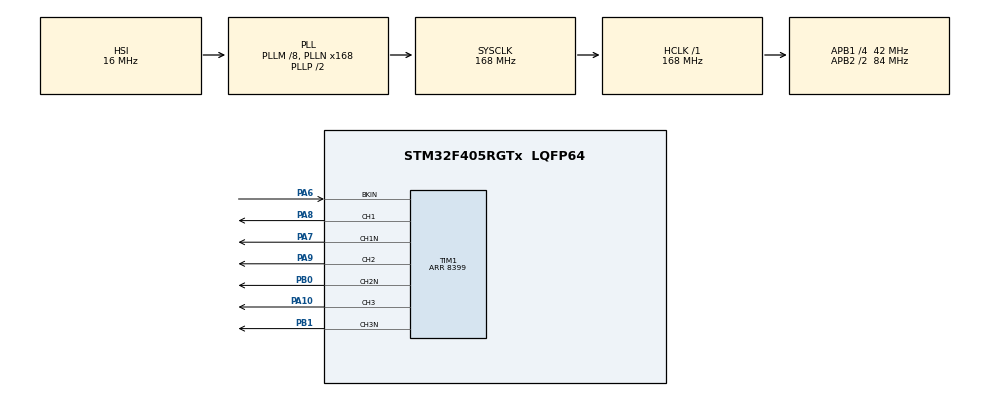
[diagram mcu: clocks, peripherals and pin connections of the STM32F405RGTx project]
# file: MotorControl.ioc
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Mcu.Family=STM32F4
Mcu.Name=STM32F405RGTx
Mcu.Package=LQFP64
NVIC.PriorityGroup=NVIC_PRIORITYGROUP_4
NVIC.TIM6_DAC_IRQn=true\:0\:0\:false\:false\:true\:true\:true\:true
PA10.Signal=S_TIM1_CH3
PA13.Mode=Serial_Wire
PA13.Signal=SYS_JTMS-SWDIO
PA14.Mode=Serial_Wire
PA14.Signal=SYS_JTCK-SWCLK
PA6.Mode=Activate-Break-Input
PA6.Signal=TIM1_BKIN
PA7.Mode=Output Compare1 CH1 CH1N
PA7.Signal=TIM1_CH1N
PA8.Signal=S_TIM1_CH1
PA9.Signal=S_TIM1_CH2
PB0.Mode=PWM Generation2 CH2 CH2N
PB0.Signal=TIM1_CH2N
PB1.Mode=Output Compare3 CH3 CH3N
PB1.Signal=TIM1_CH3N
PH0-OSC_IN.Mode=HSE-External-Oscillator
PH0-OSC_IN.Signal=RCC_OSC_IN
PH1-OSC_OUT.Mode=HSE-External-Oscillator
PH1-OSC_OUT.Signal=RCC_OSC_OUT
ProjectManager.HeapSize=0x200
ProjectManager.StackSize=0x400
ProjectManager.TargetToolchain=CMake
RCC.48MHZClocksFreq_Value=84000000
RCC.AHBFreq_Value=168000000
RCC.APB1CLKDivider=RCC_HCLK_DIV4
RCC.APB1Freq_Value=42000000
RCC.APB1TimFreq_Value=84000000
RCC.APB2CLKDivider=RCC_HCLK_DIV2
RCC.APB2Freq_Value=84000000
RCC.APB2TimFreq_Value=168000000
RCC.CortexFreq_Value=168000000
RCC.HCLKFreq_Value=168000000
RCC.HSE_VALUE=25000000
RCC.HSI_VALUE=16000000
RCC.LSE_VALUE=32768
RCC.PLLM=8
RCC.PLLN=168
RCC.SYSCLKFreq_VALUE=168000000
RCC.SYSCLKSource=RCC_SYSCLKSOURCE_PLLCLK
RCC.VCOOutputFreq_Value=336000000
SH.S_TIM1_CH1.0=TIM1_CH1,Output Compare1 CH1 CH1N
SH.S_TIM1_CH2.0=TIM1_CH2,PWM Generation2 CH2 CH2N
SH.S_TIM1_CH3.0=TIM1_CH3,Output Compare3 CH3 CH3N
TIM1.AutoReloadPreload=TIM_AUTORELOAD_PRELOAD_ENABLE
TIM1.AutomaticOutput=TIM_AUTOMATICOUTPUT_ENABLE
TIM1.BreakPolarity=TIM_BREAKPOLARITY_LOW
TIM1.Channel-Output\ Compare1\ CH1\ CH1N=TIM_CHANNEL_1
TIM1.Channel-Output\ Compare3\ CH3\ CH3N=TIM_CHANNEL_3
TIM1.Channel-PWM\ Generation2\ CH2\ CH2N=TIM_CHANNEL_2
TIM1.LockLevel=TIM_LOCKLEVEL_1
TIM1.OffStateIDLEMode=TIM_OSSI_ENABLE
TIM1.OffStateRunMode=TIM_OSSR_ENABLE
TIM1.Period=8399
TIM6.Period=999
TIM6.Prescaler=83
VP_TIM1_VS_ClockSourceINT.Mode=Internal
VP_TIM6_VS_ClockSourceINT.Mode=Enable_Timer
board=custom

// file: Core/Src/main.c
/* USER CODE BEGIN Header */
/**
 ******************************************************************************
 * @file           : main.c
 * @brief          : Main program body
 ******************************************************************************
 * @attention
 *
 * Copyright (c) 2026 STMicroelectronics.
 * All rights reserved.
 *
 * This software is licensed under terms that can be found in the LICENSE file
 * in the root directory of this software component.
 * If no LICENSE file comes with this software, it is provided AS-IS.
 *
 ******************************************************************************
 */
/* USER CODE END Header */
#include "main.h"

#include "gpio.h"
#include "tim.h"

/* USER CODE BEGIN Includes */
#include "bsp_motor.h"
/* USER CODE END Includes */

/* USER CODE BEGIN PV */
Motor_TypeDef my_motor;
/* USER CODE END PV */

void SystemClock_Config(void);

/* USER CODE BEGIN 0 */
void HAL_TIM_PeriodElapsedCallback(TIM_HandleTypeDef* htim) {
    if (htim->Instance == TIM6) {
        Motor_Loop(&my_motor);
        if (my_motor.current_speed < my_motor.target_speed) {
            my_motor.current_speed += 1.0f;
        }
        my_motor.pulse_count += my_motor.current_speed;
    }
}
/* USER CODE END 0 */

int main(void) {

    /* MCU
     * Configuration--------------------------------------------------------*/

    /* Reset of all peripherals, Initializes the Flash interface and the
     * Systick. */
    HAL_Init();

    /* Configure the system clock */
    SystemClock_Config();

    /* Initialize all configured peripherals */
    MX_GPIO_Init();
    MX_TIM1_Init();
    MX_TIM6_Init();
    /* USER CODE BEGIN 2 */
    HAL_TIM_PWM_Start(&htim1, TIM_CHANNEL_1);
    HAL_TIM_Base_Start_IT(&htim6);
    Motor_Init(&my_motor);
    /* USER CODE END 2 */

    /* Infinite loop */
    while (1) {

    }
}

void SystemClock_Config(void) {
    RCC_OscInitTypeDef RCC_OscInitStruct = {0};
    RCC_ClkInitTypeDef RCC_ClkInitStruct = {0};

    /** Configure the main internal regulator output voltage
     */
    __HAL_RCC_PWR_CLK_ENABLE();
    __HAL_PWR_VOLTAGESCALING_CONFIG(PWR_REGULATOR_VOLTAGE_SCALE1);

    /** Initializes the RCC Oscillators according to the specified parameters
     * in the RCC_OscInitTypeDef structure.
     */
    RCC_OscInitStruct.OscillatorType = RCC_OSCILLATORTYPE_HSI;
    RCC_OscInitStruct.HSIState = RCC_HSI_ON;
    RCC_OscInitStruct.HSICalibrationValue = RCC_HSICALIBRATION_DEFAULT;
    RCC_OscInitStruct.PLL.PLLState = RCC_PLL_ON;
    RCC_OscInitStruct.PLL.PLLSource = RCC_PLLSOURCE_HSI;
    RCC_OscInitStruct.PLL.PLLM = 8;
    RCC_OscInitStruct.PLL.PLLN = 168;
    RCC_OscInitStruct.PLL.PLLP = RCC_PLLP_DIV2;
    RCC_OscInitStruct.PLL.PLLQ = 4;
    if (HAL_RCC_OscConfig(&RCC_OscInitStruct) != HAL_OK) {
        Error_Handler();
    }

    /** Initializes the CPU, AHB and APB buses clocks
     */
    RCC_ClkInitStruct.ClockType = RCC_CLOCKTYPE_HCLK | RCC_CLOCKTYPE_SYSCLK |
                                  RCC_CLOCKTYPE_PCLK1 | RCC_CLOCKTYPE_PCLK2;
    RCC_ClkInitStruct.SYSCLKSource = RCC_SYSCLKSOURCE_PLLCLK;
    RCC_ClkInitStruct.AHBCLKDivider = RCC_SYSCLK_DIV1;
    RCC_ClkInitStruct.APB1CLKDivider = RCC_HCLK_DIV4;
    RCC_ClkInitStruct.APB2CLKDivider = RCC_HCLK_DIV2;

    if (HAL_RCC_ClockConfig(&RCC_ClkInitStruct, FLASH_LATENCY_5) != HAL_OK) {
        Error_Handler();
    }
}

void Error_Handler(void) {
    /* USER CODE BEGIN Error_Handler_Debug */
    /* User can add his own implementation to report the HAL error return state
     */
    __disable_irq();
    while (1) {
    }
    /* USER CODE END Error_Handler_Debug */
}
#ifdef USE_FULL_ASSERT
/**
 * @brief  Reports the name of the source file and the source line number
 *         where the assert_param error has occurred.
 * @param  file: pointer to the source file name
 * @param  line: assert_param error line source number
 * @retval None
 */
void assert_failed(uint8_t* file, uint32_t line) {
    /* USER CODE BEGIN 6 */
    /* User can add his own implementation to report the file name and line
       number, ex: printf("Wrong parameters value: file %s on line %d\r\n",
       file, line) */
    /* USER CODE END 6 */
}
#endif /* USE_FULL_ASSERT */
